# PIC32MK0512MCF064 register map
Vendor: Microchip
Registers are 32-bit, read-write, reset 0x0 unless marked. A register's access mark holds for its fields unless they carry their own. Addresses are absolute, and some are shared; only a register's first bit layout is shown; [hi:lo] are bit positions.

## TMR4
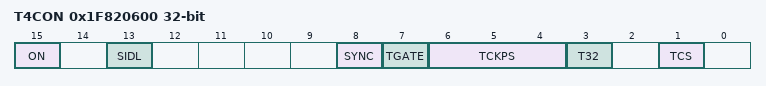
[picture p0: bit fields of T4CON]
0x1F820600 T4CON reset not defined — Timer Configuration (power-on value ----------------000----x00000-0-)
  [15] ON — Timer On bit
    1=Module is enabled; 0=Module is disabled
  [13] SIDL — Stop in Idle Mode bit
    1=Discontinue operation when device enters Idle mode; 0=Continue operation even in Idle mode
  [8] SYNC — Synchronized Timer Start/Stop Enable bit
    1=Synchronized timer Start/Stop is enabled; 0=Synchronized timer Start/Stop is disabled
  [7] TGATE — Timer Gated Time Accumulation Enable bit
    1=Gated time accumulation is enabled; 0=Gated time accumulation is disabled
  [6:4] TCKPS — Timer Input Clock Prescale Select bits
    7=1:256 prescale value; 6=1:64 prescale value; 5=1:32 prescale value; 4=1:16 prescale value; 3=1:8 prescale value; 2=1:4 prescale value; 1=1:2 prescale value; 0=1:1 prescale value
  [3] T32 — 32-Bit Timer Mode Select bit
    1=32-bit Timer mode; 0=16-bit Timer mode
  [1] TCS — Timer Clock Source Select bit
    1=External clock from TxCK pin; 0=Internal peripheral clock
0x1F820610 TMR4 — Timer
0x1F820620 PR4 reset 0xFFFFFFFF — Timer Period

## TMR5
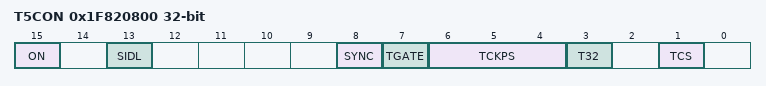
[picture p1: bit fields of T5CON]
0x1F820800 T5CON reset not defined — Timer Configuration (power-on value ----------------000----x00000-0-)
  [15] ON — Timer On bit
    1=Module is enabled; 0=Module is disabled
  [13] SIDL — Stop in Idle Mode bit
    1=Discontinue operation when device enters Idle mode; 0=Continue operation even in Idle mode
  [8] SYNC — Synchronized Timer Start/Stop Enable bit
    1=Synchronized timer Start/Stop is enabled; 0=Synchronized timer Start/Stop is disabled
  [7] TGATE — Timer Gated Time Accumulation Enable bit
    1=Gated time accumulation is enabled; 0=Gated time accumulation is disabled
  [6:4] TCKPS — Timer Input Clock Prescale Select bits
    7=1:256 prescale value; 6=1:64 prescale value; 5=1:32 prescale value; 4=1:16 prescale value; 3=1:8 prescale value; 2=1:4 prescale value; 1=1:2 prescale value; 0=1:1 prescale value
  [3] T32 — 32-Bit Timer Mode Select bit
    1=32-bit Timer mode; 0=16-bit Timer mode
  [1] TCS — Timer Clock Source Select bit
    1=External clock from TxCK pin; 0=Internal peripheral clock
0x1F820810 TMR5 — Timer
0x1F820820 PR5 reset 0xFFFFFFFF — Timer Period

## TMR6
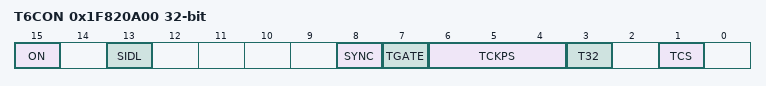
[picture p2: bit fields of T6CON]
0x1F820A00 T6CON reset not defined — Timer Configuration (power-on value ----------------000----x00000-0-)
  [15] ON — Timer On bit
    1=Module is enabled; 0=Module is disabled
  [13] SIDL — Stop in Idle Mode bit
    1=Discontinue operation when device enters Idle mode; 0=Continue operation even in Idle mode
  [8] SYNC — Synchronized Timer Start/Stop Enable bit
    1=Synchronized timer Start/Stop is enabled; 0=Synchronized timer Start/Stop is disabled
  [7] TGATE — Timer Gated Time Accumulation Enable bit
    1=Gated time accumulation is enabled; 0=Gated time accumulation is disabled
  [6:4] TCKPS — Timer Input Clock Prescale Select bits
    7=1:256 prescale value; 6=1:64 prescale value; 5=1:32 prescale value; 4=1:16 prescale value; 3=1:8 prescale value; 2=1:4 prescale value; 1=1:2 prescale value; 0=1:1 prescale value
  [3] T32 — 32-Bit Timer Mode Select bit
    1=32-bit Timer mode; 0=16-bit Timer mode
  [1] TCS — Timer Clock Source Select bit
    1=External clock from TxCK pin; 0=Internal peripheral clock
0x1F820A10 TMR6 — Timer
0x1F820A20 PR6 reset 0xFFFFFFFF — Timer Period

## TMR7
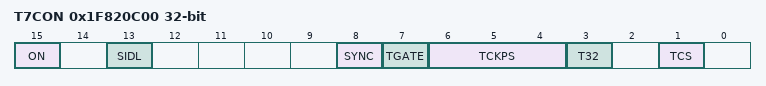
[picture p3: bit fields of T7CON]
0x1F820C00 T7CON reset not defined — Timer Configuration (power-on value ----------------000----x00000-0-)
  [15] ON — Timer On bit
    1=Module is enabled; 0=Module is disabled
  [13] SIDL — Stop in Idle Mode bit
    1=Discontinue operation when device enters Idle mode; 0=Continue operation even in Idle mode
  [8] SYNC — Synchronized Timer Start/Stop Enable bit
    1=Synchronized timer Start/Stop is enabled; 0=Synchronized timer Start/Stop is disabled
  [7] TGATE — Timer Gated Time Accumulation Enable bit
    1=Gated time accumulation is enabled; 0=Gated time accumulation is disabled
  [6:4] TCKPS — Timer Input Clock Prescale Select bits
    7=1:256 prescale value; 6=1:64 prescale value; 5=1:32 prescale value; 4=1:16 prescale value; 3=1:8 prescale value; 2=1:4 prescale value; 1=1:2 prescale value; 0=1:1 prescale value
  [3] T32 — 32-Bit Timer Mode Select bit
    1=32-bit Timer mode; 0=16-bit Timer mode
  [1] TCS — Timer Clock Source Select bit
    1=External clock from TxCK pin; 0=Internal peripheral clock
0x1F820C10 TMR7 — Timer
0x1F820C20 PR7 reset 0xFFFFFFFF — Timer Period
